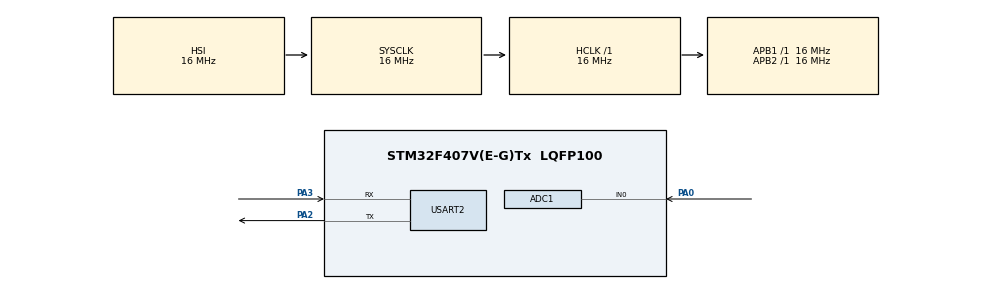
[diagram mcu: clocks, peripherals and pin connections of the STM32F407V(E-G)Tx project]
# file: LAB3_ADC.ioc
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ADC1.Channel-0\#ChannelRegularConversion=ADC_CHANNEL_0
ADC1.Channel-1\#ChannelRegularConversion=ADC_CHANNEL_0
ADC1.Channel-2\#ChannelRegularConversion=ADC_CHANNEL_0
ADC1.Channel-3\#ChannelInjectedConversion=ADC_CHANNEL_VREFINT
ADC1.Channel-4\#ChannelInjectedConversion=ADC_CHANNEL_TEMPSENSOR
ADC1.Channel-5\#ChannelInjectedConversion=ADC_CHANNEL_0
ADC1.InjNumberOfConversion=3
ADC1.InjectedOffset-3\#ChannelInjectedConversion=0
ADC1.InjectedOffset-4\#ChannelInjectedConversion=0
ADC1.InjectedOffset-5\#ChannelInjectedConversion=0
ADC1.InjectedRank-3\#ChannelInjectedConversion=1
ADC1.InjectedRank-4\#ChannelInjectedConversion=2
ADC1.InjectedRank-5\#ChannelInjectedConversion=3
ADC1.NbrOfConversion=3
ADC1.NbrOfConversionFlag=1
ADC1.Rank-0\#ChannelRegularConversion=1
ADC1.Rank-1\#ChannelRegularConversion=2
ADC1.Rank-2\#ChannelRegularConversion=3
ADC1.SamplingTime-0\#ChannelRegularConversion=ADC_SAMPLETIME_15CYCLES
ADC1.SamplingTime-1\#ChannelRegularConversion=ADC_SAMPLETIME_15CYCLES
ADC1.SamplingTime-2\#ChannelRegularConversion=ADC_SAMPLETIME_15CYCLES
ADC1.SamplingTime-3\#ChannelInjectedConversion=ADC_SAMPLETIME_15CYCLES
ADC1.SamplingTime-4\#ChannelInjectedConversion=ADC_SAMPLETIME_15CYCLES
ADC1.SamplingTime-5\#ChannelInjectedConversion=ADC_SAMPLETIME_15CYCLES
ADC1.master=1
Mcu.Family=STM32F4
Mcu.Name=STM32F407V(E-G)Tx
Mcu.Package=LQFP100
NVIC.PriorityGroup=NVIC_PRIORITYGROUP_4
PA0-WKUP.Signal=ADCx_IN0
PA13.Mode=Serial_Wire
PA13.Signal=SYS_JTMS-SWDIO
PA14.Mode=Serial_Wire
PA14.Signal=SYS_JTCK-SWCLK
PA2.Mode=Asynchronous
PA2.Signal=USART2_TX
PA3.Mode=Asynchronous
PA3.Signal=USART2_RX
ProjectManager.HeapSize=0x200
ProjectManager.StackSize=0x400
ProjectManager.TargetToolchain=MDK-ARM V5.32
RCC.AHBFreq_Value=16000000
RCC.APB1Freq_Value=16000000
RCC.APB2Freq_Value=16000000
RCC.CortexFreq_Value=16000000
RCC.HSE_VALUE=25000000
RCC.HSI_VALUE=16000000
RCC.LSE_VALUE=32768
RCC.SYSCLKFreq_VALUE=16000000
RCC.VCOOutputFreq_Value=192000000
SH.ADCx_IN0.0=ADC1_IN0,IN0
USART2.VirtualMode=VM_ASYNC
VP_ADC1_TempSens_Input.Mode=IN-TempSens
VP_ADC1_Vref_Input.Mode=IN-Vrefint
board=custom

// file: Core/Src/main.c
/* USER CODE BEGIN Header */
/**
  ******************************************************************************
  * @file           : main.c
  * @brief          : Main program body
  ******************************************************************************
  * @attention
  *
  * Copyright (c) 2023 STMicroelectronics.
  * All rights reserved.
  *
  * This software is licensed under terms that can be found in the LICENSE file
  * in the root directory of this software component.
  * If no LICENSE file comes with this software, it is provided AS-IS.
  *
  ******************************************************************************
  */
/* USER CODE END Header */
#include "main.h"
#include "adc.h"
#include "usart.h"
#include "gpio.h"

/* USER CODE BEGIN Includes */
#include <stdio.h>
#include <string.h>
/* USER CODE END Includes */

/* USER CODE BEGIN PD */
#define PUTCHAR_PROTOTYPE int fputc(int ch, FILE *f)
/* USER CODE END PD */

/* USER CODE BEGIN PM */
PUTCHAR_PROTOTYPE
{
	HAL_UART_Transmit(&huart2, (uint8_t *)&ch, 1, 0xFFFF);
	return ch;
}
/* USER CODE END PM */

/* USER CODE BEGIN PV */
float power_mcu;
float temperature;
float pin_io;
/* USER CODE END PV */

void SystemClock_Config(void);

int main(void)
{

  /* MCU Configuration--------------------------------------------------------*/

  /* Reset of all peripherals, Initializes the Flash interface and the Systick. */
  HAL_Init();

  /* Configure the system clock */
  SystemClock_Config();

  /* Initialize all configured peripherals */
  MX_GPIO_Init();
  MX_ADC1_Init();
  MX_USART2_UART_Init();
  /* USER CODE BEGIN 2 */
		uint8_t message[] = "Hello it's Dima\r\n";
		HAL_UART_Transmit(&huart2, message, sizeof(message), 1000);
  /* USER CODE END 2 */

  /* Infinite loop */
  /* USER CODE BEGIN WHILE */
	uint8_t msg[] = {"12:35:00\r"};
	uint8_t hours = 0;
	uint8_t minutes = 0;
	uint8_t seconds = 0;
	uint8_t seconds_trigger = 0;
  while (1)
  {
		seconds++;
		seconds_trigger++;
		if(seconds == 60)
		{
			seconds = 0;
			minutes ++;
			if (minutes == 60)
			{
				hours ++;
				if (hours == 24)
				{
					hours = 0;
				}
			}
		}

		uint32_t temp_result_0;
		uint32_t temp_result_1;
		uint32_t temp_result_2;

		HAL_ADCEx_InjectedStart(&hadc1);
		HAL_ADCEx_InjectedPollForConversion(&hadc1, 1000);
		temp_result_0 = HAL_ADCEx_InjectedGetValue(&hadc1, ADC_INJECTED_RANK_1);
		temp_result_1 = HAL_ADCEx_InjectedGetValue(&hadc1, ADC_INJECTED_RANK_2);
		temp_result_2 = HAL_ADCEx_InjectedGetValue(&hadc1, ADC_INJECTED_RANK_3);
		HAL_ADCEx_InjectedStop(&hadc1);

		power_mcu = 1.21 * 4095 / temp_result_0;
		pin_io = power_mcu * temp_result_1 / 4095;
		temperature = 1 / 0.0025 * (power_mcu * temp_result_1 / 4095 - 0.76) + 25;
		HAL_Delay(1000);
		if (seconds_trigger == 10)
		{
			seconds_trigger = 0;
			printf("%2d:%2d:%2d %.1f degrees Celcius\r\n",hours, minutes, seconds, temperature);
		}
    /* USER CODE END WHILE */

  }
}

void SystemClock_Config(void)
{
  RCC_OscInitTypeDef RCC_OscInitStruct = {0};
  RCC_ClkInitTypeDef RCC_ClkInitStruct = {0};

  /** Configure the main internal regulator output voltage
  */
  __HAL_RCC_PWR_CLK_ENABLE();
  __HAL_PWR_VOLTAGESCALING_CONFIG(PWR_REGULATOR_VOLTAGE_SCALE1);

  /** Initializes the RCC Oscillators according to the specified parameters
  * in the RCC_OscInitTypeDef structure.
  */
  RCC_OscInitStruct.OscillatorType = RCC_OSCILLATORTYPE_HSI;
  RCC_OscInitStruct.HSIState = RCC_HSI_ON;
  RCC_OscInitStruct.HSICalibrationValue = RCC_HSICALIBRATION_DEFAULT;
  RCC_OscInitStruct.PLL.PLLState = RCC_PLL_NONE;
  if (HAL_RCC_OscConfig(&RCC_OscInitStruct) != HAL_OK)
  {
    Error_Handler();
  }

  /** Initializes the CPU, AHB and APB buses clocks
  */
  RCC_ClkInitStruct.ClockType = RCC_CLOCKTYPE_HCLK|RCC_CLOCKTYPE_SYSCLK
                              |RCC_CLOCKTYPE_PCLK1|RCC_CLOCKTYPE_PCLK2;
  RCC_ClkInitStruct.SYSCLKSource = RCC_SYSCLKSOURCE_HSI;
  RCC_ClkInitStruct.AHBCLKDivider = RCC_SYSCLK_DIV1;
  RCC_ClkInitStruct.APB1CLKDivider = RCC_HCLK_DIV1;
  RCC_ClkInitStruct.APB2CLKDivider = RCC_HCLK_DIV1;

  if (HAL_RCC_ClockConfig(&RCC_ClkInitStruct, FLASH_LATENCY_0) != HAL_OK)
  {
    Error_Handler();
  }
}

void Error_Handler(void)
{
  __disable_irq();
  while (1)
  {
  }
}
